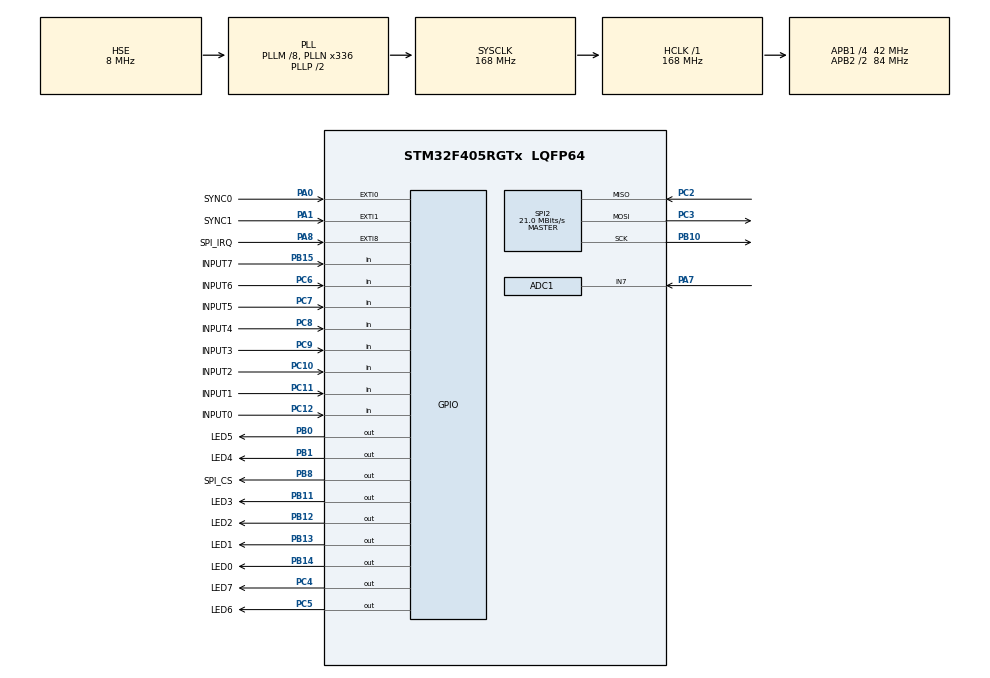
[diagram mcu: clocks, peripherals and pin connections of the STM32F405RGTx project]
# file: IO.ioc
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ADC1.Channel-0\#ChannelRegularConversion=ADC_CHANNEL_7
ADC1.ContinuousConvMode=ENABLE
ADC1.DMAContinuousRequests=ENABLE
ADC1.NbrOfConversion=1
ADC1.NbrOfConversionFlag=1
ADC1.Rank-0\#ChannelRegularConversion=1
ADC1.SamplingTime-0\#ChannelRegularConversion=ADC_SAMPLETIME_3CYCLES
ADC1.master=1
Dma.ADC1.0.Direction=DMA_PERIPH_TO_MEMORY
Dma.ADC1.0.FIFOMode=DMA_FIFOMODE_DISABLE
Dma.ADC1.0.Instance=DMA2_Stream0
Dma.ADC1.0.MemDataAlignment=DMA_MDATAALIGN_HALFWORD
Dma.ADC1.0.MemInc=DMA_MINC_ENABLE
Dma.ADC1.0.Mode=DMA_NORMAL
Dma.ADC1.0.PeriphDataAlignment=DMA_PDATAALIGN_HALFWORD
Dma.ADC1.0.PeriphInc=DMA_PINC_DISABLE
Dma.ADC1.0.Priority=DMA_PRIORITY_HIGH
Dma.Request0=ADC1
Mcu.Family=STM32F4
Mcu.Name=STM32F405RGTx
Mcu.Package=LQFP64
NVIC.DMA2_Stream0_IRQn=true\:0\:0\:false\:false\:true\:false\:true\:true
NVIC.EXTI0_IRQn=true\:0\:0\:false\:false\:true\:true\:true\:true
NVIC.EXTI1_IRQn=true\:2\:0\:true\:false\:true\:true\:true\:true
NVIC.EXTI9_5_IRQn=true\:1\:0\:true\:false\:true\:true\:true\:true
NVIC.PriorityGroup=NVIC_PRIORITYGROUP_2
NVIC.TIM2_IRQn=true\:2\:0\:true\:false\:true\:true\:true\:true
PA0-WKUP.GPIO_Label=SYNC0
PA0-WKUP.GPIO_ModeDefaultEXTI=GPIO_MODE_IT_FALLING
PA0-WKUP.Signal=GPXTI0
PA1.GPIO_Label=SYNC1
PA1.GPIO_ModeDefaultEXTI=GPIO_MODE_IT_FALLING
PA1.Signal=GPXTI1
PA13.Mode=Serial_Wire
PA13.Signal=SYS_JTMS-SWDIO
PA14.Mode=Serial_Wire
PA14.Signal=SYS_JTCK-SWCLK
PA7.Signal=ADCx_IN7
PA8.GPIO_Label=SPI_IRQ
PA8.GPIO_ModeDefaultEXTI=GPIO_MODE_IT_FALLING
PA8.Signal=GPXTI8
PB0.GPIO_Label=LED5
PB0.Signal=GPIO_Output
PB1.GPIO_Label=LED4
PB1.Signal=GPIO_Output
PB10.GPIO_PuPd=GPIO_NOPULL
PB10.Mode=Full_Duplex_Master
PB10.Signal=SPI2_SCK
PB11.GPIO_Label=LED3
PB11.Signal=GPIO_Output
PB12.GPIO_Label=LED2
PB12.Signal=GPIO_Output
PB13.GPIO_Label=LED1
PB13.Signal=GPIO_Output
PB14.GPIO_Label=LED0
PB14.Signal=GPIO_Output
PB15.GPIO_Label=INPUT7
PB15.GPIO_PuPd=GPIO_PULLDOWN
PB15.Signal=GPIO_Input
PB8.GPIO_Label=SPI_CS
PB8.GPIO_PuPd=GPIO_PULLUP
PB8.GPIO_Speed=GPIO_SPEED_FREQ_LOW
PB8.PinState=GPIO_PIN_SET
PB8.Signal=GPIO_Output
PC10.GPIO_Label=INPUT2
PC10.GPIO_PuPd=GPIO_PULLDOWN
PC10.Signal=GPIO_Input
PC11.GPIO_Label=INPUT1
PC11.GPIO_PuPd=GPIO_PULLDOWN
PC11.Signal=GPIO_Input
PC12.GPIO_Label=INPUT0
PC12.GPIO_PuPd=GPIO_PULLDOWN
PC12.Signal=GPIO_Input
PC2.Mode=Full_Duplex_Master
PC2.Signal=SPI2_MISO
PC3.Mode=Full_Duplex_Master
PC3.Signal=SPI2_MOSI
PC4.GPIO_Label=LED7
PC4.Signal=GPIO_Output
PC5.GPIO_Label=LED6
PC5.Signal=GPIO_Output
PC6.GPIO_Label=INPUT6
PC6.GPIO_PuPd=GPIO_PULLDOWN
PC6.Signal=GPIO_Input
PC7.GPIO_Label=INPUT5
PC7.GPIO_PuPd=GPIO_PULLDOWN
PC7.Signal=GPIO_Input
PC8.GPIO_Label=INPUT4
PC8.GPIO_PuPd=GPIO_PULLDOWN
PC8.Signal=GPIO_Input
PC9.GPIO_Label=INPUT3
PC9.GPIO_PuPd=GPIO_PULLDOWN
PC9.Signal=GPIO_Input
PH0-OSC_IN.Mode=HSE-External-Oscillator
PH0-OSC_IN.Signal=RCC_OSC_IN
PH1-OSC_OUT.Mode=HSE-External-Oscillator
PH1-OSC_OUT.Signal=RCC_OSC_OUT
ProjectManager.HeapSize=0x2000
ProjectManager.StackSize=0x2000
ProjectManager.TargetToolchain=MDK-ARM V5.32
RCC.48MHZClocksFreq_Value=84000000
RCC.AHBFreq_Value=168000000
RCC.APB1CLKDivider=RCC_HCLK_DIV4
RCC.APB1Freq_Value=42000000
RCC.APB1TimFreq_Value=84000000
RCC.APB2CLKDivider=RCC_HCLK_DIV2
RCC.APB2Freq_Value=84000000
RCC.APB2TimFreq_Value=168000000
RCC.CortexFreq_Value=168000000
RCC.HCLKFreq_Value=168000000
RCC.HSE_VALUE=8000000
RCC.HSI_VALUE=16000000
RCC.LSE_VALUE=32768
RCC.PLLM=8
RCC.PLLN=336
RCC.PLLSourceVirtual=RCC_PLLSOURCE_HSE
RCC.SYSCLKFreq_VALUE=168000000
RCC.SYSCLKSource=RCC_SYSCLKSOURCE_PLLCLK
RCC.VCOOutputFreq_Value=336000000
SH.ADCx_IN7.0=ADC1_IN7,IN7
SPI2.CLKPhase=SPI_PHASE_2EDGE
SPI2.CLKPolarity=SPI_POLARITY_HIGH
SPI2.CRCCalculation=SPI_CRCCALCULATION_DISABLE
SPI2.CalculateBaudRate=21.0 MBits/s
SPI2.Direction=SPI_DIRECTION_2LINES
SPI2.Mode=SPI_MODE_MASTER
SPI2.VirtualType=VM_MASTER
TIM2.AutoReloadPreload=TIM_AUTORELOAD_PRELOAD_ENABLE
TIM2.Period=1000
TIM2.Prescaler=83
VP_TIM2_VS_ClockSourceINT.Mode=Internal
board=custom

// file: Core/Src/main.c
/* USER CODE BEGIN Header */
/**
  ******************************************************************************
  * @file           : main.c
  * @brief          : Main program body
  ******************************************************************************
  * @attention
  *
  * Copyright (c) 2023 STMicroelectronics.
  * All rights reserved.
  *
  * This software is licensed under terms that can be found in the LICENSE file
  * in the root directory of this software component.
  * If no LICENSE file comes with this software, it is provided AS-IS.
  *
  ******************************************************************************
  */
/* USER CODE END Header */
#include "main.h"
#include "adc.h"
#include "dma.h"
#include "spi.h"
#include "tim.h"
#include "gpio.h"

/* USER CODE BEGIN Includes */

#include "el9800appl.h"
/* USER CODE END Includes */

/* USER CODE BEGIN PM */
volatile uint16_t uhADCxConvertedValue;
/* USER CODE END PM */

void SystemClock_Config(void);

int main(void)
{

  /* MCU Configuration--------------------------------------------------------*/

  /* Reset of all peripherals, Initializes the Flash interface and the Systick. */
  HAL_Init();

  /* Configure the system clock */
  SystemClock_Config();

  /* Initialize all configured peripherals */
  MX_GPIO_Init();
  MX_DMA_Init();
  MX_TIM2_Init();
  MX_SPI2_Init();
  MX_ADC1_Init();
  /* USER CODE BEGIN 2 */
//	HAL_ADC_Start_DMA(&hadc1,(uint32_t *)&uhADCxConvertedValue,1);

	ECT_main();//ethercat主函数
  /* USER CODE END 2 */

  /* Infinite loop */
  while (1)
  {

  }
}

void SystemClock_Config(void)
{
  RCC_OscInitTypeDef RCC_OscInitStruct = {0};
  RCC_ClkInitTypeDef RCC_ClkInitStruct = {0};

  /** Configure the main internal regulator output voltage
  */
  __HAL_RCC_PWR_CLK_ENABLE();
  __HAL_PWR_VOLTAGESCALING_CONFIG(PWR_REGULATOR_VOLTAGE_SCALE1);

  /** Initializes the RCC Oscillators according to the specified parameters
  * in the RCC_OscInitTypeDef structure.
  */
  RCC_OscInitStruct.OscillatorType = RCC_OSCILLATORTYPE_HSE;
  RCC_OscInitStruct.HSEState = RCC_HSE_ON;
  RCC_OscInitStruct.PLL.PLLState = RCC_PLL_ON;
  RCC_OscInitStruct.PLL.PLLSource = RCC_PLLSOURCE_HSE;
  RCC_OscInitStruct.PLL.PLLM = 8;
  RCC_OscInitStruct.PLL.PLLN = 336;
  RCC_OscInitStruct.PLL.PLLP = RCC_PLLP_DIV2;
  RCC_OscInitStruct.PLL.PLLQ = 4;
  if (HAL_RCC_OscConfig(&RCC_OscInitStruct) != HAL_OK)
  {
    Error_Handler();
  }

  /** Initializes the CPU, AHB and APB buses clocks
  */
  RCC_ClkInitStruct.ClockType = RCC_CLOCKTYPE_HCLK|RCC_CLOCKTYPE_SYSCLK
                              |RCC_CLOCKTYPE_PCLK1|RCC_CLOCKTYPE_PCLK2;
  RCC_ClkInitStruct.SYSCLKSource = RCC_SYSCLKSOURCE_PLLCLK;
  RCC_ClkInitStruct.AHBCLKDivider = RCC_SYSCLK_DIV1;
  RCC_ClkInitStruct.APB1CLKDivider = RCC_HCLK_DIV4;
  RCC_ClkInitStruct.APB2CLKDivider = RCC_HCLK_DIV2;

  if (HAL_RCC_ClockConfig(&RCC_ClkInitStruct, FLASH_LATENCY_5) != HAL_OK)
  {
    Error_Handler();
  }
}

void Error_Handler(void)
{
  __disable_irq();
  while (1)
  {
  }
}
